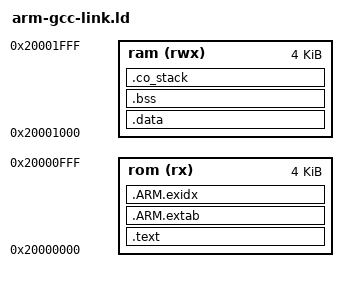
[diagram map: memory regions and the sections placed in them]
OUTPUT_FORMAT ("elf32-littlearm", "elf32-bigarm", "elf32-littlearm")
/* Internal Memory Map*/
MEMORY
{
	rom (rx)  : ORIGIN = 0x20000000, LENGTH = 0x00001000
	ram (rwx) : ORIGIN = 0x20001000, LENGTH = 0x00001000
}

_eram = 0x20002800 + 0x00002000;
/* Section Definitions */ 
SECTIONS 
{ 
    .text : 
    { 
        KEEP(*(.isr_vector .isr_vector.*)) 
        *(.text .text.* .gnu.linkonce.t.*) 	      
        *(.glue_7t) *(.glue_7)		                
        *(.rodata .rodata* .gnu.linkonce.r.*)		    	                  
    } > rom
    
    .ARM.extab : 
    {
        *(.ARM.extab* .gnu.linkonce.armextab.*)
    } > rom
    
    __exidx_start = .;
    .ARM.exidx :
    {
        *(.ARM.exidx* .gnu.linkonce.armexidx.*)
    } > rom
    __exidx_end = .;
    
    . = ALIGN(4); 
    _etext = .;
    _sidata = .; 
    		
    .data : AT (_etext) 
    { 
        _sdata = .; 
        *(.data .data.*) 
        . = ALIGN(4); 
        _edata = . ;
    } > ram

    /* .bss section which is used for uninitialized data */ 
    .bss (NOLOAD) : 
    { 
        _sbss = . ; 
        *(.bss .bss.*) 
        *(COMMON) 
        . = ALIGN(4); 
        _ebss = . ; 
    } > ram
    
    /* stack section */
    .co_stack (NOLOAD):
    {
        . = ALIGN(8);
        *(.co_stack .co_stack.*)
    } > ram
       
    . = ALIGN(4); 
    _end = . ; 
} 
